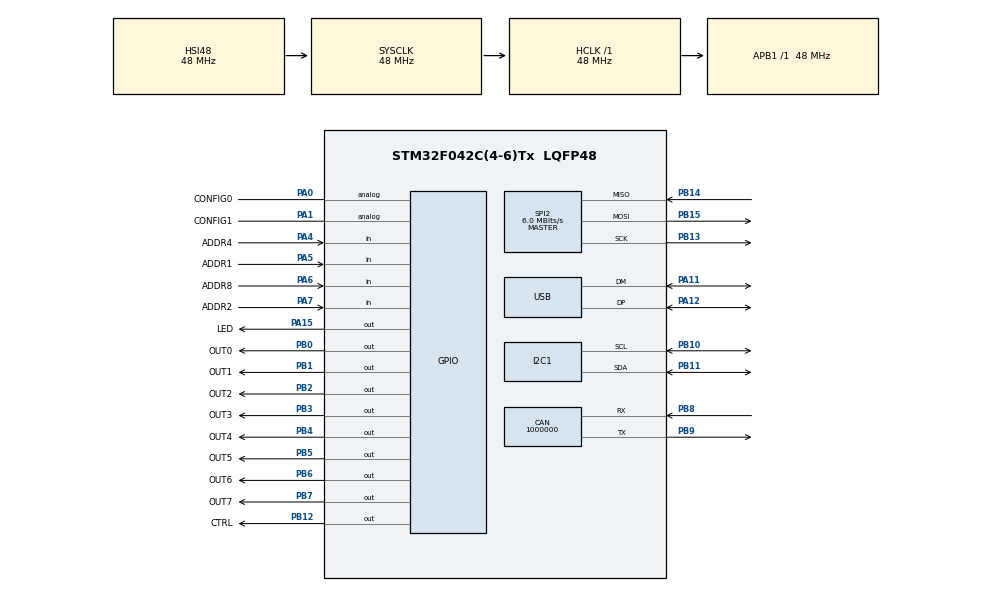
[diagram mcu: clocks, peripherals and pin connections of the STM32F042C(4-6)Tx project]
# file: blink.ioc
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CAN.BS1=CAN_BS1_1TQ
CAN.BS2=CAN_BS2_1TQ
CAN.CalculateBaudRate=1000000
CAN.CalculateTimeBit=1000
CAN.CalculateTimeQuantum=333.3333333333333
CAN.NART=ENABLE
Mcu.Family=STM32F0
Mcu.Name=STM32F042C(4-6)Tx
Mcu.Package=LQFP48
NVIC.USB_IRQn=true\:0\:0\:false\:false\:true\:false\:true\:true
PA0.GPIO_Label=CONFIG0
PA0.Signal=GPIO_Analog
PA1.GPIO_Label=CONFIG1
PA1.Signal=GPIO_Analog
PA11.Mode=Device
PA11.Signal=USB_DM
PA12.Mode=Device
PA12.Signal=USB_DP
PA15.GPIO_Label=LED
PA15.Signal=GPIO_Output
PA4.GPIO_Label=ADDR4
PA4.GPIO_PuPd=GPIO_PULLDOWN
PA4.Signal=GPIO_Input
PA5.GPIO_Label=ADDR1
PA5.GPIO_PuPd=GPIO_PULLDOWN
PA5.Signal=GPIO_Input
PA6.GPIO_Label=ADDR8
PA6.GPIO_PuPd=GPIO_PULLDOWN
PA6.Signal=GPIO_Input
PA7.GPIO_Label=ADDR2
PA7.GPIO_PuPd=GPIO_PULLDOWN
PA7.Signal=GPIO_Input
PB0.GPIO_Label=OUT0
PB0.Signal=GPIO_Output
PB1.GPIO_Label=OUT1
PB1.Signal=GPIO_Output
PB10.Mode=I2C
PB10.Signal=I2C1_SCL
PB11.Mode=I2C
PB11.Signal=I2C1_SDA
PB12.GPIO_Label=CTRL
PB12.PinState=GPIO_PIN_SET
PB12.Signal=GPIO_Output
PB13.Mode=Full_Duplex_Master
PB13.Signal=SPI2_SCK
PB14.Mode=Full_Duplex_Master
PB14.Signal=SPI2_MISO
PB15.Mode=Full_Duplex_Master
PB15.Signal=SPI2_MOSI
PB2.GPIO_Label=OUT2
PB2.Signal=GPIO_Output
PB3.GPIO_Label=OUT3
PB3.Signal=GPIO_Output
PB4.GPIO_Label=OUT4
PB4.Signal=GPIO_Output
PB5.GPIO_Label=OUT5
PB5.Signal=GPIO_Output
PB6.GPIO_Label=OUT6
PB6.Signal=GPIO_Output
PB7.GPIO_Label=OUT7
PB7.Signal=GPIO_Output
PB8.Mode=CAN_Activate
PB8.Signal=CAN_RX
PB9.Mode=CAN_Activate
PB9.Signal=CAN_TX
PF0-OSC_IN.Mode=HSE-External-Oscillator
PF0-OSC_IN.Signal=RCC_OSC_IN
PF1-OSC_OUT.Mode=HSE-External-Oscillator
PF1-OSC_OUT.Signal=RCC_OSC_OUT
ProjectManager.HeapSize=0x200
ProjectManager.StackSize=0x400
ProjectManager.TargetToolchain=Makefile
RCC.AHBFreq_Value=48000000
RCC.APB1Freq_Value=48000000
RCC.APB1TimFreq_Value=48000000
RCC.HCLKFreq_Value=48000000
RCC.HSE_VALUE=16000000
RCC.PLLMUL=RCC_PLL_MUL3
RCC.PLLSourceVirtual=RCC_PLLSOURCE_HSE
RCC.SYSCLKFreq_VALUE=48000000
RCC.SYSCLKSource=RCC_SYSCLKSOURCE_HSI48
SPI2.BaudRatePrescaler=SPI_BAUDRATEPRESCALER_8
SPI2.CalculateBaudRate=6.0 MBits/s
SPI2.DataSize=SPI_DATASIZE_8BIT
SPI2.Direction=SPI_DIRECTION_2LINES
SPI2.Mode=SPI_MODE_MASTER
SPI2.VirtualType=VM_MASTER
USB_DEVICE.APP_RX_DATA_SIZE=512
USB_DEVICE.APP_TX_DATA_SIZE=512
USB_DEVICE.CLASS_NAME_FS=CDC
USB_DEVICE.VirtualMode=Cdc
USB_DEVICE.VirtualModeFS=Cdc_FS
VP_USB_DEVICE_VS_USB_DEVICE_CDC_FS.Mode=CDC_FS
board=custom

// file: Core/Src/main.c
/* USER CODE BEGIN Header */
/**
    ******************************************************************************
    * @file           : main.c
    * @brief          : Main program body
    ******************************************************************************
    * @attention
    *
    * Copyright (c) 2024 STMicroelectronics.
    * All rights reserved.
    *
    * This software is licensed under terms that can be found in the LICENSE file
    * in the root directory of this software component.
    * If no LICENSE file comes with this software, it is provided AS-IS.
    *
    ******************************************************************************
    */
/* USER CODE END Header */
#include "main.h"
#include "usb_device.h"

/* USER CODE BEGIN PD */

// Set default value for delay if not specified
#ifndef DELAY
#define DELAY 500
#endif

/* USER CODE END PD */

CAN_HandleTypeDef hcan;

I2C_HandleTypeDef hi2c1;

SPI_HandleTypeDef hspi2;

void SystemClock_Config(void);
static void MX_GPIO_Init(void);
static void MX_CAN_Init(void);
static void MX_I2C1_Init(void);
static void MX_SPI2_Init(void);

int main(void)
{

  /* MCU Configuration--------------------------------------------------------*/

  /* Reset of all peripherals, Initializes the Flash interface and the Systick. */
  HAL_Init();

  /* Configure the system clock */
  SystemClock_Config();

  /* Initialize all configured peripherals */
  MX_GPIO_Init();
  MX_CAN_Init();
  MX_I2C1_Init();
  MX_SPI2_Init();
  MX_USB_DEVICE_Init();

  /* Infinite loop */
  /* USER CODE BEGIN WHILE */
    while (1)
    {
      HAL_GPIO_TogglePin(LED_GPIO_Port, LED_Pin);
      HAL_Delay(DELAY);
    /* USER CODE END WHILE */

    }
}

void SystemClock_Config(void)
{
  RCC_OscInitTypeDef RCC_OscInitStruct = {0};
  RCC_ClkInitTypeDef RCC_ClkInitStruct = {0};
  RCC_PeriphCLKInitTypeDef PeriphClkInit = {0};

  /** Initializes the RCC Oscillators according to the specified parameters
  * in the RCC_OscInitTypeDef structure.
  */
  RCC_OscInitStruct.OscillatorType = RCC_OSCILLATORTYPE_HSI|RCC_OSCILLATORTYPE_HSI48;
  RCC_OscInitStruct.HSIState = RCC_HSI_ON;
  RCC_OscInitStruct.HSI48State = RCC_HSI48_ON;
  RCC_OscInitStruct.HSICalibrationValue = RCC_HSICALIBRATION_DEFAULT;
  RCC_OscInitStruct.PLL.PLLState = RCC_PLL_NONE;
  if (HAL_RCC_OscConfig(&RCC_OscInitStruct) != HAL_OK)
  {
    Error_Handler();
  }

  /** Initializes the CPU, AHB and APB buses clocks
  */
  RCC_ClkInitStruct.ClockType = RCC_CLOCKTYPE_HCLK|RCC_CLOCKTYPE_SYSCLK
                              |RCC_CLOCKTYPE_PCLK1;
  RCC_ClkInitStruct.SYSCLKSource = RCC_SYSCLKSOURCE_HSI48;
  RCC_ClkInitStruct.AHBCLKDivider = RCC_SYSCLK_DIV1;
  RCC_ClkInitStruct.APB1CLKDivider = RCC_HCLK_DIV1;

  if (HAL_RCC_ClockConfig(&RCC_ClkInitStruct, FLASH_LATENCY_1) != HAL_OK)
  {
    Error_Handler();
  }
  PeriphClkInit.PeriphClockSelection = RCC_PERIPHCLK_USB|RCC_PERIPHCLK_I2C1;
  PeriphClkInit.I2c1ClockSelection = RCC_I2C1CLKSOURCE_HSI;
  PeriphClkInit.UsbClockSelection = RCC_USBCLKSOURCE_HSI48;

  if (HAL_RCCEx_PeriphCLKConfig(&PeriphClkInit) != HAL_OK)
  {
    Error_Handler();
  }
}

static void MX_CAN_Init(void)
{

  hcan.Instance = CAN;
  hcan.Init.Prescaler = 16;
  hcan.Init.Mode = CAN_MODE_NORMAL;
  hcan.Init.SyncJumpWidth = CAN_SJW_1TQ;
  hcan.Init.TimeSeg1 = CAN_BS1_1TQ;
  hcan.Init.TimeSeg2 = CAN_BS2_1TQ;
  hcan.Init.TimeTriggeredMode = DISABLE;
  hcan.Init.AutoBusOff = DISABLE;
  hcan.Init.AutoWakeUp = DISABLE;
  hcan.Init.AutoRetransmission = ENABLE;
  hcan.Init.ReceiveFifoLocked = DISABLE;
  hcan.Init.TransmitFifoPriority = DISABLE;
  if (HAL_CAN_Init(&hcan) != HAL_OK)
  {
    Error_Handler();
  }

}

static void MX_I2C1_Init(void)
{

  hi2c1.Instance = I2C1;
  hi2c1.Init.Timing = 0x2000090E;
  hi2c1.Init.OwnAddress1 = 0;
  hi2c1.Init.AddressingMode = I2C_ADDRESSINGMODE_7BIT;
  hi2c1.Init.DualAddressMode = I2C_DUALADDRESS_DISABLE;
  hi2c1.Init.OwnAddress2 = 0;
  hi2c1.Init.OwnAddress2Masks = I2C_OA2_NOMASK;
  hi2c1.Init.GeneralCallMode = I2C_GENERALCALL_DISABLE;
  hi2c1.Init.NoStretchMode = I2C_NOSTRETCH_DISABLE;
  if (HAL_I2C_Init(&hi2c1) != HAL_OK)
  {
    Error_Handler();
  }

  /** Configure Analogue filter
  */
  if (HAL_I2CEx_ConfigAnalogFilter(&hi2c1, I2C_ANALOGFILTER_ENABLE) != HAL_OK)
  {
    Error_Handler();
  }

  /** Configure Digital filter
  */
  if (HAL_I2CEx_ConfigDigitalFilter(&hi2c1, 0) != HAL_OK)
  {
    Error_Handler();
  }

}

static void MX_SPI2_Init(void)
{

  /* SPI2 parameter configuration*/
  hspi2.Instance = SPI2;
  hspi2.Init.Mode = SPI_MODE_MASTER;
  hspi2.Init.Direction = SPI_DIRECTION_2LINES;
  hspi2.Init.DataSize = SPI_DATASIZE_8BIT;
  hspi2.Init.CLKPolarity = SPI_POLARITY_LOW;
  hspi2.Init.CLKPhase = SPI_PHASE_1EDGE;
  hspi2.Init.NSS = SPI_NSS_SOFT;
  hspi2.Init.BaudRatePrescaler = SPI_BAUDRATEPRESCALER_8;
  hspi2.Init.FirstBit = SPI_FIRSTBIT_MSB;
  hspi2.Init.TIMode = SPI_TIMODE_DISABLE;
  hspi2.Init.CRCCalculation = SPI_CRCCALCULATION_DISABLE;
  hspi2.Init.CRCPolynomial = 7;
  hspi2.Init.CRCLength = SPI_CRC_LENGTH_DATASIZE;
  hspi2.Init.NSSPMode = SPI_NSS_PULSE_ENABLE;
  if (HAL_SPI_Init(&hspi2) != HAL_OK)
  {
    Error_Handler();
  }

}

static void MX_GPIO_Init(void)
{
  GPIO_InitTypeDef GPIO_InitStruct = {0};

  /* GPIO Ports Clock Enable */
  __HAL_RCC_GPIOF_CLK_ENABLE();
  __HAL_RCC_GPIOA_CLK_ENABLE();
  __HAL_RCC_GPIOB_CLK_ENABLE();

  /*Configure GPIO pin Output Level */
  HAL_GPIO_WritePin(GPIOB, OUT0_Pin|OUT1_Pin|OUT2_Pin|OUT3_Pin
                          |OUT4_Pin|OUT5_Pin|OUT6_Pin|OUT7_Pin, GPIO_PIN_RESET);

  /*Configure GPIO pin Output Level */
  HAL_GPIO_WritePin(CTRL_GPIO_Port, CTRL_Pin, GPIO_PIN_SET);

  /*Configure GPIO pin Output Level */
  HAL_GPIO_WritePin(LED_GPIO_Port, LED_Pin, GPIO_PIN_RESET);

  /*Configure GPIO pins : CONFIG0_Pin CONFIG1_Pin */
  GPIO_InitStruct.Pin = CONFIG0_Pin|CONFIG1_Pin;
  GPIO_InitStruct.Mode = GPIO_MODE_ANALOG;
  GPIO_InitStruct.Pull = GPIO_NOPULL;
  HAL_GPIO_Init(GPIOA, &GPIO_InitStruct);

  /*Configure GPIO pins : ADDR4_Pin ADDR1_Pin ADDR8_Pin ADDR2_Pin */
  GPIO_InitStruct.Pin = ADDR4_Pin|ADDR1_Pin|ADDR8_Pin|ADDR2_Pin;
  GPIO_InitStruct.Mode = GPIO_MODE_INPUT;
  GPIO_InitStruct.Pull = GPIO_PULLDOWN;
  HAL_GPIO_Init(GPIOA, &GPIO_InitStruct);

  /*Configure GPIO pins : OUT0_Pin OUT1_Pin OUT2_Pin CTRL_Pin
                           OUT3_Pin OUT4_Pin OUT5_Pin OUT6_Pin
                           OUT7_Pin */
  GPIO_InitStruct.Pin = OUT0_Pin|OUT1_Pin|OUT2_Pin|CTRL_Pin
                          |OUT3_Pin|OUT4_Pin|OUT5_Pin|OUT6_Pin
                          |OUT7_Pin;
  GPIO_InitStruct.Mode = GPIO_MODE_OUTPUT_PP;
  GPIO_InitStruct.Pull = GPIO_NOPULL;
  GPIO_InitStruct.Speed = GPIO_SPEED_FREQ_LOW;
  HAL_GPIO_Init(GPIOB, &GPIO_InitStruct);

  /*Configure GPIO pin : LED_Pin */
  GPIO_InitStruct.Pin = LED_Pin;
  GPIO_InitStruct.Mode = GPIO_MODE_OUTPUT_PP;
  GPIO_InitStruct.Pull = GPIO_NOPULL;
  GPIO_InitStruct.Speed = GPIO_SPEED_FREQ_LOW;
  HAL_GPIO_Init(LED_GPIO_Port, &GPIO_InitStruct);

}

void Error_Handler(void)
{
    __disable_irq();
    while (1)
    {
    }
}
